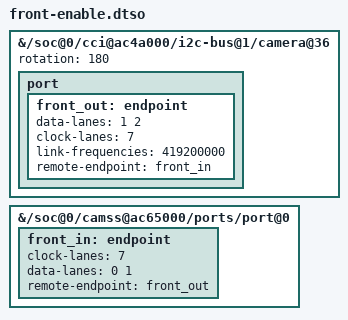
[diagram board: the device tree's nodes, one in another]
/dts-v1/;
/plugin/;
/ {
 fragment@0 {
  target-path = "/soc@0/cci@ac4a000/i2c-bus@1/camera@36";
  __overlay__ {
   status = "okay";
   rotation = <180>;
   port {
    front_out: endpoint {
     data-lanes = <1 2>;
     clock-lanes = <7>;
     link-frequencies = /bits/ 64 <419200000>;
     remote-endpoint = <&front_in>;
    };
   };
  };
 };
 fragment@1 {
  target-path = "/soc@0/camss@ac65000/ports/port@0";
  __overlay__ {
   front_in: endpoint {
    clock-lanes = <7>;
    data-lanes = <0 1>;
    remote-endpoint = <&front_out>;
   };
  };
 };
};
